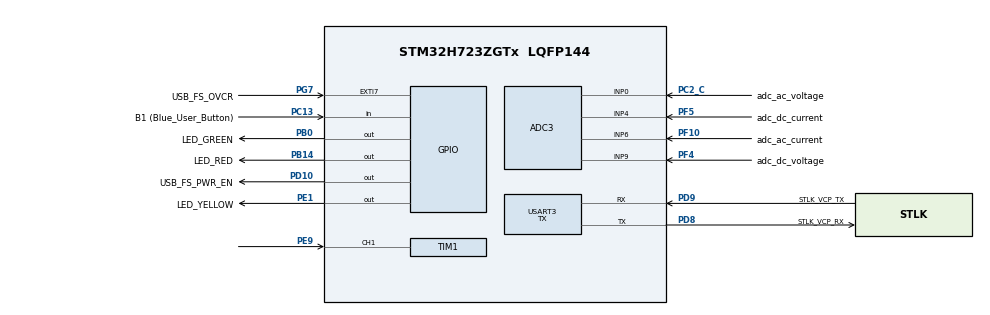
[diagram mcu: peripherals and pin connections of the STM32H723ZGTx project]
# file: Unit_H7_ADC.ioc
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ADC3.Channel-1\#ChannelRegularConversion=ADC_CHANNEL_0
ADC3.ClockPrescaler=ADC_CLOCK_ASYNC_DIV1
ADC3.ContinuousConvMode=ENABLE
ADC3.ConversionDataManagement=ADC_CONVERSIONDATA_DR
ADC3.DMAContinuousRequests=DISABLE
ADC3.EOCSelection=ADC_EOC_SEQ_CONV
ADC3.ExternalTrigConv=ADC_SOFTWARE_START
ADC3.NbrOfConversion=1
ADC3.NbrOfConversionFlag=1
ADC3.OffsetNumber-1\#ChannelRegularConversion=ADC_OFFSET_NONE
ADC3.OffsetSaturation-1\#ChannelRegularConversion=DISABLE
ADC3.OffsetSign-1\#ChannelRegularConversion=ADC3_OFFSET_SIGN_NEGATIVE
ADC3.OffsetSignedSaturation-1\#ChannelRegularConversion=DISABLE
ADC3.Overrun=ADC_OVR_DATA_OVERWRITTEN
ADC3.Rank-1\#ChannelRegularConversion=1
ADC3.SamplingTime-1\#ChannelRegularConversion=ADC3_SAMPLETIME_2CYCLES_5
CORTEX_M7.CPU_DCache=Enabled
CORTEX_M7.CPU_ICache=Enabled
Dma.Request0=USART3_TX
Dma.USART3_TX.0.Direction=DMA_MEMORY_TO_PERIPH
Dma.USART3_TX.0.EventEnable=DISABLE
Dma.USART3_TX.0.FIFOMode=DMA_FIFOMODE_DISABLE
Dma.USART3_TX.0.Instance=DMA1_Stream0
Dma.USART3_TX.0.MemDataAlignment=DMA_MDATAALIGN_BYTE
Dma.USART3_TX.0.MemInc=DMA_MINC_ENABLE
Dma.USART3_TX.0.Mode=DMA_NORMAL
Dma.USART3_TX.0.PeriphDataAlignment=DMA_PDATAALIGN_BYTE
Dma.USART3_TX.0.PeriphInc=DMA_PINC_DISABLE
Dma.USART3_TX.0.Polarity=HAL_DMAMUX_REQ_GEN_RISING
Dma.USART3_TX.0.Priority=DMA_PRIORITY_LOW
Dma.USART3_TX.0.RequestNumber=1
Dma.USART3_TX.0.SignalID=NONE
Dma.USART3_TX.0.SyncEnable=DISABLE
Dma.USART3_TX.0.SyncPolarity=HAL_DMAMUX_SYNC_NO_EVENT
Dma.USART3_TX.0.SyncRequestNumber=1
Dma.USART3_TX.0.SyncSignalID=NONE
Mcu.Family=STM32H7
Mcu.Name=STM32H723ZGTx
Mcu.Package=LQFP144
NVIC.ADC3_IRQn=true\:0\:0\:false\:false\:true\:true\:true
NVIC.DMA1_Stream0_IRQn=true\:0\:0\:false\:false\:true\:false\:true
NVIC.PriorityGroup=NVIC_PRIORITYGROUP_4
NVIC.TIM1_UP_IRQn=true\:0\:0\:false\:false\:true\:true\:true
PA13(JTMS/SWDIO).GPIO_Label=SWDIO
PA13(JTMS/SWDIO).Mode=Trace_Asynchronous_SW
PA13(JTMS/SWDIO).Signal=DEBUG_JTMS-SWDIO
PA14(JTCK/SWCLK).GPIO_Label=SWCLK
PA14(JTCK/SWCLK).Mode=Trace_Asynchronous_SW
PA14(JTCK/SWCLK).Signal=DEBUG_JTCK-SWCLK
PB0.GPIO_Label=LED_GREEN
PB0.Signal=GPIO_Output
PB14.GPIO_Label=LED_RED
PB14.Signal=GPIO_Output
PB3(JTDO/TRACESWO).GPIO_Label=SWO
PB3(JTDO/TRACESWO).Mode=Trace_Asynchronous_SW
PB3(JTDO/TRACESWO).Signal=DEBUG_JTDO-SWO
PC13.GPIO_Label=B1 (Blue_User_Button)
PC13.Signal=GPIO_Input
PC14-OSC32_IN.Mode=LSE-External-Oscillator
PC14-OSC32_IN.Signal=RCC_OSC32_IN
PC15-OSC32_OUT.Mode=LSE-External-Oscillator
PC15-OSC32_OUT.Signal=RCC_OSC32_OUT
PC2_C.GPIO_Label=adc_ac_voltage
PC2_C.Mode=IN0-Single-Ended
PC2_C.Signal=ADC3_INP0
PD10.GPIO_Label=USB_FS_PWR_EN
PD10.Signal=GPIO_Output
PD8.GPIO_Label=STLK_VCP_RX
PD8.Mode=Asynchronous
PD8.Signal=USART3_TX
PD9.GPIO_Label=STLK_VCP_TX
PD9.Mode=Asynchronous
PD9.Signal=USART3_RX
PE1.GPIO_Label=LED_YELLOW
PE1.Signal=GPIO_Output
PE9.Signal=S_TIM1_CH1
PF10.GPIO_Label=adc_ac_current
PF10.Mode=IN6-Single-Ended
PF10.Signal=ADC3_INP6
PF4.GPIO_Label=adc_dc_voltage
PF4.Mode=IN9-Single-Ended
PF4.Signal=ADC3_INP9
PF5.GPIO_Label=adc_dc_current
PF5.Mode=IN4-Single-Ended
PF5.Signal=ADC3_INP4
PG7.GPIO_Label=USB_FS_OVCR
PG7.Signal=GPXTI7
PH0-OSC_IN.GPIO_Label=MCO
PH0-OSC_IN.Mode=HSE-External-Clock-Source
PH0-OSC_IN.Signal=RCC_OSC_IN
ProjectManager.HeapSize=0x200
ProjectManager.StackSize=0x400
ProjectManager.TargetToolchain=STM32CubeIDE
RCC.ADCFreq_Value=96000000
RCC.APB1Freq_Value=137500000
RCC.APB2Freq_Value=137500000
RCC.APB3Freq_Value=137500000
RCC.APB4Freq_Value=137500000
RCC.CortexFreq_Value=550000000
RCC.D1PPRE=RCC_APB3_DIV2
RCC.D2PPRE1=RCC_APB1_DIV2
RCC.D2PPRE2=RCC_APB2_DIV2
RCC.D3PPRE=RCC_APB4_DIV2
RCC.DIVM1=4
RCC.DIVM2=1
RCC.DIVN1=275
RCC.DIVN2=24
RCC.DIVP1=1
RCC.DIVQ1=4
RCC.HCLKFreq_Value=275000000
RCC.HPRE=RCC_HCLK_DIV2
RCC.HSE_VALUE=8000000
RCC.PLLFRACN=0
RCC.PLLSourceVirtual=RCC_PLLSOURCE_HSE
RCC.SYSCLKFreq_VALUE=550000000
RCC.SYSCLKSource=RCC_SYSCLKSOURCE_PLLCLK
RCC.USBCLockSelection=RCC_USBCLKSOURCE_HSI48
RCC.USBFreq_Value=48000000
SH.S_TIM1_CH1.0=TIM1_CH1,Input_Capture1_from_TI1
TIM1.Channel-Input_Capture1_from_TI1=TIM_CHANNEL_1
TIM1.Period=11000
USART3.Mode=MODE_TX
USART3.VirtualMode-Asynchronous=VM_ASYNC
VP_TIM1_VS_ClockSourceINT.Mode=Internal
board=NUCLEO-H723ZG

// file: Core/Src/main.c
/* USER CODE BEGIN Header */
/**
  ******************************************************************************
  * @file           : main.c
  * @brief          : Main program body
  ******************************************************************************
  * @attention
  *
  * <h2><center>&copy; Copyright (c) 2021 STMicroelectronics.
  * All rights reserved.</center></h2>
  *
  * This software component is licensed by ST under BSD 3-Clause license,
  * the "License"; You may not use this file except in compliance with the
  * License. You may obtain a copy of the License at:
  *                        opensource.org/licenses/BSD-3-Clause
  *
  ******************************************************************************
  */
/* USER CODE END Header */
#include "main.h"

/* USER CODE BEGIN Includes */
#include "stdlib.h"
#include "string.h"
/* USER CODE END Includes */

/* USER CODE BEGIN PD */
#define ADC_LENGTH 2
/* USER CODE END PD */

ADC_HandleTypeDef hadc3;

TIM_HandleTypeDef htim1;

UART_HandleTypeDef huart3;
DMA_HandleTypeDef hdma_usart3_tx;

/* USER CODE BEGIN PV */
uint16_t adc_memory[ADC_LENGTH] = {0};
/* USER CODE END PV */

void SystemClock_Config(void);
static void MX_GPIO_Init(void);
static void MX_USART3_UART_Init(void);
static void MX_ADC3_Init(void);
static void MX_DMA_Init(void);
static void MX_TIM1_Init(void);

/* USER CODE BEGIN 0 */
void HAL_TIM_PeriodElapsedCallback(TIM_HandleTypeDef *htim)
{
	HAL_ADC_Start(&hadc3);
	HAL_ADC_PollForConversion(&hadc3, 1);

	adc_memory[0] = HAL_ADC_GetValue(&hadc3);

	/* Code voor sensor hier */

	char str[6] = "000000";
	char end[2] = "\r\n";
	itoa(adc_memory[0], str, 10);

	HAL_UART_Transmit(&huart3, (uint8_t* )str, strlen(str), 1);
	HAL_UART_Transmit(&huart3, (uint8_t* )end, strlen(end), 1);

}

/* USER CODE END 0 */

int main(void)
{

  /* Enable I-Cache---------------------------------------------------------*/
  SCB_EnableICache();

  /* Enable D-Cache---------------------------------------------------------*/
  SCB_EnableDCache();

  /* MCU Configuration--------------------------------------------------------*/

  /* Reset of all peripherals, Initializes the Flash interface and the Systick. */
  HAL_Init();

  /* Configure the system clock */
  SystemClock_Config();

  /* USER CODE BEGIN SysInit */
  /* disable D-cache, causes problems with DMA */
  //SCB_DisableDCache();
  /* USER CODE END SysInit */

  /* Initialize all configured peripherals */
  MX_GPIO_Init();
  MX_USART3_UART_Init();
  MX_ADC3_Init();
  MX_DMA_Init();
  MX_TIM1_Init();
  /* USER CODE BEGIN 2 */
  HAL_TIM_Base_Start_IT(&htim1);
  /* USER CODE END 2 */

  /* Infinite loop */
  while (1)
  {

  }
}

void SystemClock_Config(void)
{
  RCC_OscInitTypeDef RCC_OscInitStruct = {0};
  RCC_ClkInitTypeDef RCC_ClkInitStruct = {0};

  /** Supply configuration update enable
  */
  HAL_PWREx_ConfigSupply(PWR_LDO_SUPPLY);
  /** Configure the main internal regulator output voltage
  */
  __HAL_PWR_VOLTAGESCALING_CONFIG(PWR_REGULATOR_VOLTAGE_SCALE0);

  while(!__HAL_PWR_GET_FLAG(PWR_FLAG_VOSRDY)) {}
  /** Macro to configure the PLL clock source
  */
  __HAL_RCC_PLL_PLLSOURCE_CONFIG(RCC_PLLSOURCE_HSE);
  /** Initializes the RCC Oscillators according to the specified parameters
  * in the RCC_OscInitTypeDef structure.
  */
  RCC_OscInitStruct.OscillatorType = RCC_OSCILLATORTYPE_HSE;
  RCC_OscInitStruct.HSEState = RCC_HSE_BYPASS;
  RCC_OscInitStruct.PLL.PLLState = RCC_PLL_ON;
  RCC_OscInitStruct.PLL.PLLSource = RCC_PLLSOURCE_HSE;
  RCC_OscInitStruct.PLL.PLLM = 4;
  RCC_OscInitStruct.PLL.PLLN = 275;
  RCC_OscInitStruct.PLL.PLLP = 1;
  RCC_OscInitStruct.PLL.PLLQ = 4;
  RCC_OscInitStruct.PLL.PLLR = 2;
  RCC_OscInitStruct.PLL.PLLRGE = RCC_PLL1VCIRANGE_1;
  RCC_OscInitStruct.PLL.PLLVCOSEL = RCC_PLL1VCOWIDE;
  RCC_OscInitStruct.PLL.PLLFRACN = 0;
  if (HAL_RCC_OscConfig(&RCC_OscInitStruct) != HAL_OK)
  {
    Error_Handler();
  }
  /** Initializes the CPU, AHB and APB buses clocks
  */
  RCC_ClkInitStruct.ClockType = RCC_CLOCKTYPE_HCLK|RCC_CLOCKTYPE_SYSCLK
                              |RCC_CLOCKTYPE_PCLK1|RCC_CLOCKTYPE_PCLK2
                              |RCC_CLOCKTYPE_D3PCLK1|RCC_CLOCKTYPE_D1PCLK1;
  RCC_ClkInitStruct.SYSCLKSource = RCC_SYSCLKSOURCE_PLLCLK;
  RCC_ClkInitStruct.SYSCLKDivider = RCC_SYSCLK_DIV1;
  RCC_ClkInitStruct.AHBCLKDivider = RCC_HCLK_DIV2;
  RCC_ClkInitStruct.APB3CLKDivider = RCC_APB3_DIV2;
  RCC_ClkInitStruct.APB1CLKDivider = RCC_APB1_DIV2;
  RCC_ClkInitStruct.APB2CLKDivider = RCC_APB2_DIV2;
  RCC_ClkInitStruct.APB4CLKDivider = RCC_APB4_DIV2;

  if (HAL_RCC_ClockConfig(&RCC_ClkInitStruct, FLASH_LATENCY_3) != HAL_OK)
  {
    Error_Handler();
  }
}

static void MX_ADC3_Init(void)
{

  ADC_ChannelConfTypeDef sConfig = {0};

  /** Common config
  */
  hadc3.Instance = ADC3;
  hadc3.Init.ClockPrescaler = ADC_CLOCK_ASYNC_DIV1;
  hadc3.Init.Resolution = ADC_RESOLUTION_12B;
  hadc3.Init.DataAlign = ADC3_DATAALIGN_RIGHT;
  hadc3.Init.ScanConvMode = ADC_SCAN_DISABLE;
  hadc3.Init.EOCSelection = ADC_EOC_SEQ_CONV;
  hadc3.Init.LowPowerAutoWait = DISABLE;
  hadc3.Init.ContinuousConvMode = ENABLE;
  hadc3.Init.NbrOfConversion = 1;
  hadc3.Init.DiscontinuousConvMode = DISABLE;
  hadc3.Init.ExternalTrigConv = ADC_SOFTWARE_START;
  hadc3.Init.ExternalTrigConvEdge = ADC_EXTERNALTRIGCONVEDGE_NONE;
  hadc3.Init.DMAContinuousRequests = DISABLE;
  hadc3.Init.SamplingMode = ADC_SAMPLING_MODE_NORMAL;
  hadc3.Init.ConversionDataManagement = ADC_CONVERSIONDATA_DR;
  hadc3.Init.Overrun = ADC_OVR_DATA_OVERWRITTEN;
  hadc3.Init.LeftBitShift = ADC_LEFTBITSHIFT_NONE;
  hadc3.Init.OversamplingMode = DISABLE;
  if (HAL_ADC_Init(&hadc3) != HAL_OK)
  {
    Error_Handler();
  }
  /** Configure Regular Channel
  */
  sConfig.Channel = ADC_CHANNEL_0;
  sConfig.Rank = ADC_REGULAR_RANK_1;
  sConfig.SamplingTime = ADC3_SAMPLETIME_2CYCLES_5;
  sConfig.SingleDiff = ADC_SINGLE_ENDED;
  sConfig.OffsetNumber = ADC_OFFSET_NONE;
  sConfig.Offset = 0;
  sConfig.OffsetSignedSaturation = DISABLE;
  sConfig.OffsetSign = ADC3_OFFSET_SIGN_NEGATIVE;
  sConfig.OffsetSaturation = DISABLE;
  if (HAL_ADC_ConfigChannel(&hadc3, &sConfig) != HAL_OK)
  {
    Error_Handler();
  }

}

static void MX_TIM1_Init(void)
{

  TIM_ClockConfigTypeDef sClockSourceConfig = {0};
  TIM_MasterConfigTypeDef sMasterConfig = {0};
  TIM_IC_InitTypeDef sConfigIC = {0};

  htim1.Instance = TIM1;
  htim1.Init.Prescaler = 0;
  htim1.Init.CounterMode = TIM_COUNTERMODE_UP;
  htim1.Init.Period = 60000;
  htim1.Init.ClockDivision = TIM_CLOCKDIVISION_DIV1;
  htim1.Init.RepetitionCounter = 0;
  htim1.Init.AutoReloadPreload = TIM_AUTORELOAD_PRELOAD_DISABLE;
  if (HAL_TIM_Base_Init(&htim1) != HAL_OK)
  {
    Error_Handler();
  }
  sClockSourceConfig.ClockSource = TIM_CLOCKSOURCE_INTERNAL;
  if (HAL_TIM_ConfigClockSource(&htim1, &sClockSourceConfig) != HAL_OK)
  {
    Error_Handler();
  }
  if (HAL_TIM_IC_Init(&htim1) != HAL_OK)
  {
    Error_Handler();
  }
  sMasterConfig.MasterOutputTrigger = TIM_TRGO_RESET;
  sMasterConfig.MasterOutputTrigger2 = TIM_TRGO2_RESET;
  sMasterConfig.MasterSlaveMode = TIM_MASTERSLAVEMODE_DISABLE;
  if (HAL_TIMEx_MasterConfigSynchronization(&htim1, &sMasterConfig) != HAL_OK)
  {
    Error_Handler();
  }
  sConfigIC.ICPolarity = TIM_INPUTCHANNELPOLARITY_RISING;
  sConfigIC.ICSelection = TIM_ICSELECTION_DIRECTTI;
  sConfigIC.ICPrescaler = TIM_ICPSC_DIV1;
  sConfigIC.ICFilter = 0;
  if (HAL_TIM_IC_ConfigChannel(&htim1, &sConfigIC, TIM_CHANNEL_1) != HAL_OK)
  {
    Error_Handler();
  }

}

static void MX_USART3_UART_Init(void)
{

  huart3.Instance = USART3;
  huart3.Init.BaudRate = 115200;
  huart3.Init.WordLength = UART_WORDLENGTH_8B;
  huart3.Init.StopBits = UART_STOPBITS_1;
  huart3.Init.Parity = UART_PARITY_NONE;
  huart3.Init.Mode = UART_MODE_TX;
  huart3.Init.HwFlowCtl = UART_HWCONTROL_NONE;
  huart3.Init.OverSampling = UART_OVERSAMPLING_16;
  huart3.Init.OneBitSampling = UART_ONE_BIT_SAMPLE_DISABLE;
  huart3.Init.ClockPrescaler = UART_PRESCALER_DIV1;
  huart3.AdvancedInit.AdvFeatureInit = UART_ADVFEATURE_NO_INIT;
  if (HAL_UART_Init(&huart3) != HAL_OK)
  {
    Error_Handler();
  }
  if (HAL_UARTEx_SetTxFifoThreshold(&huart3, UART_TXFIFO_THRESHOLD_1_8) != HAL_OK)
  {
    Error_Handler();
  }
  if (HAL_UARTEx_SetRxFifoThreshold(&huart3, UART_RXFIFO_THRESHOLD_1_8) != HAL_OK)
  {
    Error_Handler();
  }
  if (HAL_UARTEx_DisableFifoMode(&huart3) != HAL_OK)
  {
    Error_Handler();
  }

}

static void MX_DMA_Init(void)
{

  /* DMA controller clock enable */
  __HAL_RCC_DMA1_CLK_ENABLE();

  /* DMA interrupt init */
  /* DMA1_Stream0_IRQn interrupt configuration */
  HAL_NVIC_SetPriority(DMA1_Stream0_IRQn, 0, 0);
  HAL_NVIC_EnableIRQ(DMA1_Stream0_IRQn);

}

static void MX_GPIO_Init(void)
{
  GPIO_InitTypeDef GPIO_InitStruct = {0};

  /* GPIO Ports Clock Enable */
  __HAL_RCC_GPIOC_CLK_ENABLE();
  __HAL_RCC_GPIOF_CLK_ENABLE();
  __HAL_RCC_GPIOH_CLK_ENABLE();
  __HAL_RCC_GPIOB_CLK_ENABLE();
  __HAL_RCC_GPIOE_CLK_ENABLE();
  __HAL_RCC_GPIOD_CLK_ENABLE();
  __HAL_RCC_GPIOG_CLK_ENABLE();
  __HAL_RCC_GPIOA_CLK_ENABLE();

  /*Configure GPIO pin Output Level */
  HAL_GPIO_WritePin(GPIOB, LED_GREEN_Pin|LED_RED_Pin, GPIO_PIN_RESET);

  /*Configure GPIO pin Output Level */
  HAL_GPIO_WritePin(USB_FS_PWR_EN_GPIO_Port, USB_FS_PWR_EN_Pin, GPIO_PIN_RESET);

  /*Configure GPIO pin Output Level */
  HAL_GPIO_WritePin(LED_YELLOW_GPIO_Port, LED_YELLOW_Pin, GPIO_PIN_RESET);

  /*Configure GPIO pin : B1_Pin */
  GPIO_InitStruct.Pin = B1_Pin;
  GPIO_InitStruct.Mode = GPIO_MODE_INPUT;
  GPIO_InitStruct.Pull = GPIO_NOPULL;
  HAL_GPIO_Init(B1_GPIO_Port, &GPIO_InitStruct);

  /*Configure GPIO pins : LED_GREEN_Pin LED_RED_Pin */
  GPIO_InitStruct.Pin = LED_GREEN_Pin|LED_RED_Pin;
  GPIO_InitStruct.Mode = GPIO_MODE_OUTPUT_PP;
  GPIO_InitStruct.Pull = GPIO_NOPULL;
  GPIO_InitStruct.Speed = GPIO_SPEED_FREQ_LOW;
  HAL_GPIO_Init(GPIOB, &GPIO_InitStruct);

  /*Configure GPIO pin : USB_FS_PWR_EN_Pin */
  GPIO_InitStruct.Pin = USB_FS_PWR_EN_Pin;
  GPIO_InitStruct.Mode = GPIO_MODE_OUTPUT_PP;
  GPIO_InitStruct.Pull = GPIO_NOPULL;
  GPIO_InitStruct.Speed = GPIO_SPEED_FREQ_LOW;
  HAL_GPIO_Init(USB_FS_PWR_EN_GPIO_Port, &GPIO_InitStruct);

  /*Configure GPIO pin : USB_FS_OVCR_Pin */
  GPIO_InitStruct.Pin = USB_FS_OVCR_Pin;
  GPIO_InitStruct.Mode = GPIO_MODE_IT_RISING;
  GPIO_InitStruct.Pull = GPIO_NOPULL;
  HAL_GPIO_Init(USB_FS_OVCR_GPIO_Port, &GPIO_InitStruct);

  /*Configure GPIO pin : LED_YELLOW_Pin */
  GPIO_InitStruct.Pin = LED_YELLOW_Pin;
  GPIO_InitStruct.Mode = GPIO_MODE_OUTPUT_PP;
  GPIO_InitStruct.Pull = GPIO_NOPULL;
  GPIO_InitStruct.Speed = GPIO_SPEED_FREQ_LOW;
  HAL_GPIO_Init(LED_YELLOW_GPIO_Port, &GPIO_InitStruct);

}

void Error_Handler(void)
{
  __disable_irq();
  while (1)
  {
  }
}

/************************ (C) COPYRIGHT STMicroelectronics *****END OF FILE****/
